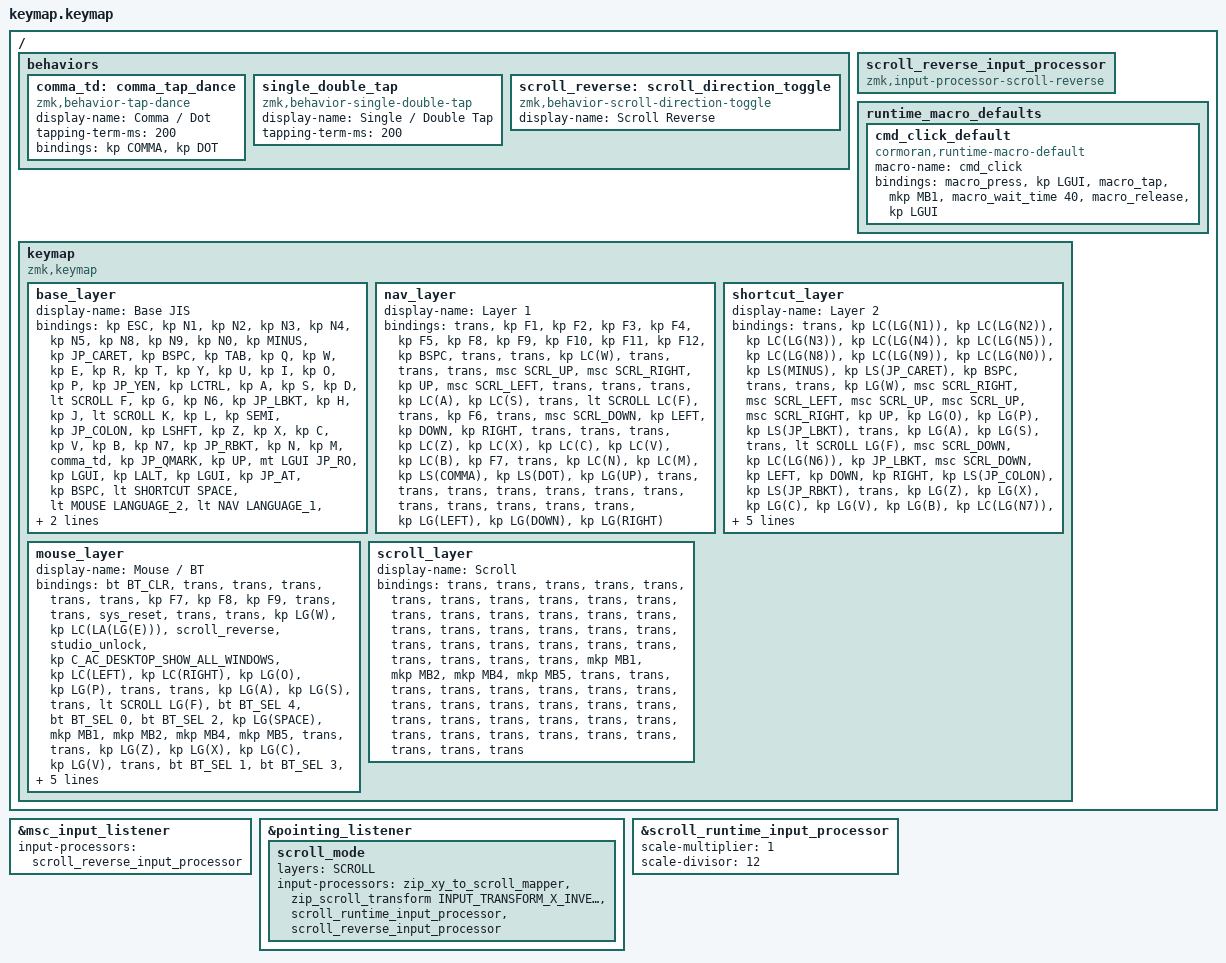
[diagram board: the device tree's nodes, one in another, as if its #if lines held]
/*
 * torabo-tsuki LP L layout (66 positions)
 * Adapted from the attached ergo68 Japanese cheat sheet.
 *
 * Binding order used by the official torabo-tsuki LP L layout:
 * row 0: 6 left + 6 right
 * row 1: 6 left + 6 right
 * row 2: 7 left + 7 right
 * row 3: 7 left + 7 right
 * row 4: 7 left + 7 right
 *
 * Host OS keyboard type must be Japanese/JIS (106/109).
 */

#include <behaviors.dtsi>
#include <behaviors/runtime_macro.dtsi>
#include <input/processors.dtsi>
#include <zephyr/dt-bindings/input/input-event-codes.h>
#include <dt-bindings/zmk/bt.h>
#include <dt-bindings/zmk/keys.h>
#include <dt-bindings/zmk/outputs.h>
#include <dt-bindings/zmk/pointing.h>
#include <dt-bindings/zmk/input_transform.h>

#define BASE      0
#define NAV       1
#define SHORTCUT  2
#define MOUSE     3
#define SCROLL    4

#if defined(CONFIG_ZMK_RUNTIME_MACRO)
#define CMD_CLICK_BINDING &rmacro 0
#else
#define CMD_CLICK_BINDING &trans
#endif

/* JIS aliases. These are HID positions interpreted by a JIS host layout. */
#define JP_CARET  EQUAL          /* ^ / ~ */
#define JP_AT     LEFT_BRACKET   /* @ / ` */
#define JP_LBKT   RIGHT_BRACKET  /* [ / { */
#define JP_RBKT   NUHS           /* ] / } */
#define JP_COLON  SQT            /* : / * */
#define JP_YEN    INT3           /* ¥ / | */
#define JP_RO     INT1           /* \ / _ (ろ key) */
#define JP_QMARK  FSLH           /* / (Shift: ?) */

/ {
    behaviors {
        /*
         * Tap Dance:
         *   single tap -> ,
         *   double tap -> .
         */
        comma_td: comma_tap_dance {
            compatible = "zmk,behavior-tap-dance";
            #binding-cells = <0>;
            display-name = "Comma / Dot";
            tapping-term-ms = <200>;
            bindings = <&kp COMMA>, <&kp DOT>;
        };

        /*
         * Runtime-selectable single/double tap for DYA Studio:
         *   param1 -> single tap key
         *   param2 -> double tap key
         */
        single_double_tap: single_double_tap {
            compatible = "zmk,behavior-single-double-tap";
            #binding-cells = <2>;
            display-name = "Single / Double Tap";
            tapping-term-ms = <200>;
        };

        scroll_reverse: scroll_direction_toggle {
            compatible = "zmk,behavior-scroll-direction-toggle";
            #binding-cells = <0>;
            display-name = "Scroll Reverse";
        };
    };

    scroll_reverse_input_processor: scroll_reverse_input_processor {
        compatible = "zmk,input-processor-scroll-reverse";
        #input-processor-cells = <0>;
    };

#if defined(CONFIG_ZMK_RUNTIME_MACRO)
    /*
     * Factory runtime macro used by the Mouse / BT layer.
     * Existing persisted macro content with the same name wins over this seed.
     *
     * cmd_click:
     *   press LGUI -> tap left click -> wait 40 ms -> release LGUI
     */
    runtime_macro_defaults {
        cmd_click_default {
            compatible = "cormoran,runtime-macro-default";
            macro-name = "cmd_click";
            bindings =
                <&macro_press &kp LGUI>,
                <&macro_tap &mkp MB1>,
                <&macro_wait_time 40>,
                <&macro_release &kp LGUI>;
        };
    };
#endif

    keymap {
        compatible = "zmk,keymap";

        base_layer {
            display-name = "Base JIS";
            bindings = <
                /*
                 * row 0
                 *
                 * Right:
                 * 8  9  0  -  ^  Backspace
                 */
                &kp ESC    &kp N1     &kp N2     &kp N3     &kp N4       &kp N5
                &kp N8     &kp N9     &kp N0     &kp MINUS  &kp JP_CARET &kp BSPC

                /* row 1 */
                &kp TAB    &kp Q      &kp W      &kp E      &kp R        &kp T
                &kp Y      &kp U      &kp I      &kp O      &kp P        &kp JP_YEN

                /*
                 * row 2
                 *
                 * Left:
                 * Ctrl  A  S  D  F  G  6
                 *
                 * F:
                 *   tap  -> F
                 *   hold -> Scroll mode
                 */
                &kp LCTRL  &kp A      &kp S      &kp D      &lt SCROLL F &kp G      &kp N6
                &kp JP_LBKT  &kp H    &kp J      &lt SCROLL K  &kp L      &kp SEMI   &kp JP_COLON

                /*
                 * row 3
                 *
                 * Left:
                 * Shift  Z  X  C  V  B  7
                 *
                 * 7 is directly below 6.
                 *
                 * Right:
                 * ]  N  M  ,  /  ↑  _
                 */
                &kp LSHFT  &kp Z      &kp X      &kp C      &kp V        &kp B      &kp N7
                &kp JP_RBKT  &kp N    &kp M      &comma_td   &kp JP_QMARK &kp UP     &mt LGUI JP_RO

                /*
                 * row 4
                 *
                 * LANGUAGE_2:
                 *   tap  -> LANGUAGE_2
                 *   hold -> Mouse / BT
                 */
                &kp LGUI   &kp LALT   &kp LGUI   &kp JP_AT
                &kp BSPC
                &lt SHORTCUT SPACE
                &lt MOUSE LANGUAGE_2

                &lt NAV LANGUAGE_1
                &kp RET
                &trans
                &trans
                &kp LEFT
                &kp DOWN
                &kp RIGHT
            >;
        };

        nav_layer {
            display-name = "Layer 1";
            bindings = <
                /*
                 * row 0
                 *
                 * Base:
                 * Esc  1  2  3  4  5 | 8  9  0  -  ^  BSPC
                 *
                 * Layer 1:
                 * --- F1 F2 F3 F4 F5 | F8 F9 F10 F11 F12 BSPC
                 */
                &trans  &kp F1     &kp F2     &kp F3     &kp F4     &kp F5
                &kp F8  &kp F9     &kp F10    &kp F11    &kp F12    &kp BSPC

                /* row 1 */
                &trans  &trans     &kp LC(W)  &trans     &trans     &trans
                &msc SCRL_UP  &msc SCRL_RIGHT  &kp UP  &msc SCRL_LEFT  &trans  &trans

                /*
                 * row 2
                 *
                 * physical 6 -> F6
                 *
                 * physical F:
                 *   tap  -> Ctrl+F
                 *   hold -> Scroll mode
                 */
                &trans  &kp LC(A)  &kp LC(S)  &trans     &lt SCROLL LC(F)  &trans  &kp F6
                &trans  &msc SCRL_DOWN  &kp LEFT  &kp DOWN  &kp RIGHT  &trans  &trans

                /*
                 * row 3
                 *
                 * physical 7 -> F7
                 */
                &trans  &kp LC(Z)  &kp LC(X)  &kp LC(C)  &kp LC(V)  &kp LC(B)  &kp F7
                &trans  &kp LC(N)  &kp LC(M)  &kp LS(COMMA)  &kp LS(DOT)  &kp LG(UP)  &trans

                /* row 4 */
                &trans  &trans     &trans     &trans     &trans     &trans     &trans
                &trans  &trans     &trans     &trans     &kp LG(LEFT)  &kp LG(DOWN)  &kp LG(RIGHT)
            >;
        };

        shortcut_layer {
            display-name = "Layer 2";
            bindings = <
                /*
                 * row 0
                 *
                 * Base 1-5 / 8-0:
                 * Ctrl + Win/Cmd + number
                 */
                &trans
                &kp LC(LG(N1))
                &kp LC(LG(N2))
                &kp LC(LG(N3))
                &kp LC(LG(N4))
                &kp LC(LG(N5))

                &kp LC(LG(N8))
                &kp LC(LG(N9))
                &kp LC(LG(N0))
                &kp LS(MINUS)
                &kp LS(JP_CARET)
                &kp BSPC

                /* row 1 */
                &trans  &trans  &kp LG(W)  &msc SCRL_RIGHT  &msc SCRL_LEFT  &msc SCRL_UP
                &msc SCRL_UP  &msc SCRL_RIGHT  &kp UP  &kp LG(O)  &kp LG(P)  &kp LS(JP_LBKT)

                /*
                 * row 2
                 *
                 * physical 6 -> Ctrl + Win/Cmd + 6
                 *
                 * physical F:
                 *   tap  -> GUI+F
                 *   hold -> Scroll mode
                 */
                &trans
                &kp LG(A)
                &kp LG(S)
                &trans
                &lt SCROLL LG(F)
                &msc SCRL_DOWN
                &kp LC(LG(N6))

                &kp JP_LBKT
                &msc SCRL_DOWN
                &kp LEFT
                &kp DOWN
                &kp RIGHT
                &kp LS(JP_COLON)
                &kp LS(JP_RBKT)

                /*
                 * row 3
                 *
                 * physical 7 -> Ctrl + Win/Cmd + 7
                 */
                &trans
                &kp LG(Z)
                &kp LG(X)
                &kp LG(C)
                &kp LG(V)
                &kp LG(B)
                &kp LC(LG(N7))

                &trans
                &kp LG(N)
                &kp LG(M)
                &kp LS(COMMA)
                &kp LS(DOT)
                &kp LG(UP)
                &kp JP_RO

                /* row 4 */
                &trans  &trans  &trans  &trans  &trans  &trans  &trans
                &trans  &trans  &trans  &trans  &kp LG(LEFT)  &kp LG(DOWN)  &kp LG(RIGHT)
            >;
        };

        /*
         * Mouse / BT
         *
         * Esc = clear selected BT profile
         * W = Cmd+W
         * E = Ctrl+Alt+Cmd+E
         * R = Scroll Reverse (RAM only)
         * T = Studio Unlock / BLE discovery
         *
         * Right number row: F7 / F8 / F9 / -- / -- / Reset
         * Y = Show All Windows (Consumer 0x29F)
         * U/I = Ctrl+Left/Right
         * O/P = Cmd+O/P
         *
         * G = BT 4, 6 = BT 0
         * [ = BT 2, H = Cmd+Space
         * J/K/L/; = Left / Right / Button4 / Button5
         * 7 = BT 1, ] = BT 3
         * Z/X/C/V and N/M use Cmd shortcuts
         * right inner thumb = runtime macro cmd_click
         */
        mouse_layer {
            display-name = "Mouse / BT";
            bindings = <
                /* row 0 */
                &bt BT_CLR  &trans  &trans  &trans  &trans  &trans
                &kp F7      &kp F8  &kp F9  &trans  &trans  &sys_reset

                /* row 1 */
                &trans
                &trans
                &kp LG(W)
                &kp LC(LA(LG(E)))
                &scroll_reverse
                &studio_unlock

                &kp C_AC_DESKTOP_SHOW_ALL_WINDOWS
                &kp LC(LEFT)
                &kp LC(RIGHT)
                &kp LG(O)
                &kp LG(P)
                &trans

                /* row 2 */
                &trans
                &kp LG(A)
                &kp LG(S)
                &trans
                &lt SCROLL LG(F)
                &bt BT_SEL 4
                &bt BT_SEL 0

                &bt BT_SEL 2
                &kp LG(SPACE)
                &mkp MB1
                &mkp MB2
                &mkp MB4
                &mkp MB5
                &trans

                /* row 3 */
                &trans
                &kp LG(Z)
                &kp LG(X)
                &kp LG(C)
                &kp LG(V)
                &trans
                &bt BT_SEL 1

                &bt BT_SEL 3
                &kp LG(N)
                &kp LG(M)
                &trans
                &trans
                &kp LG(UP)
                &trans

                /* row 4 */
                &trans  &trans  &trans  &trans  &kp BSPC  &trans  &trans

                &trans
                CMD_CLICK_BINDING
                &trans
                &trans
                &kp LG(LEFT)
                &kp LG(DOWN)
                &kp LG(RIGHT)
            >;
        };

        /*
         * Scroll layer
         *
         * F/K hold activates this layer. Most keys stay transparent; the
         * right home-row mouse buttons remain available while scrolling.
         */
        scroll_layer {
            display-name = "Scroll";
            bindings = <
                /* row 0 */
                &trans  &trans  &trans  &trans  &trans  &trans
                &trans  &trans  &trans  &trans  &trans  &trans

                /* row 1 */
                &trans  &trans  &trans  &trans  &trans  &trans
                &trans  &trans  &trans  &trans  &trans  &trans

                /* row 2 */
                &trans  &trans  &trans  &trans  &trans  &trans  &trans
                &trans  &trans  &mkp MB1  &mkp MB2  &mkp MB4  &mkp MB5  &trans

                /* row 3 */
                &trans  &trans  &trans  &trans  &trans  &trans  &trans
                &trans  &trans  &trans  &trans  &trans  &trans  &trans

                /* row 4 */
                &trans  &trans  &trans  &trans  &trans  &trans  &trans
                &trans  &trans  &trans  &trans  &trans  &trans  &trans
            >;
        };
    };
};

/*
 * Keep direct Scroll Up/Down keys at their existing speed, but run them through
 * the same final RAM-only vertical reverse processor as trackball scrolling.
 */
&msc_input_listener {
    input-processors = <&scroll_reverse_input_processor>;
};

/*
 * 通常時:
 *   Trackball X/Y -> Cursor
 *
 * F長押し中:
 *   Trackball X/Y -> Scroll
 *
 * スクロール量:
 *   DYA Studio の scroll runtime input processor で変更可能
 */
&pointing_listener {
    scroll_mode {
        layers = <SCROLL>;
        input-processors =
            <&zip_xy_to_scroll_mapper>,
            <&zip_scroll_transform INPUT_TRANSFORM_X_INVERT>,
            <&scroll_runtime_input_processor>,
            <&scroll_reverse_input_processor>;
    };
};

/* Preserve the previous scroll sensitivity as the DYA Studio default. */
&scroll_runtime_input_processor {
    scale-multiplier = <1>;
    scale-divisor = <12>;
};
